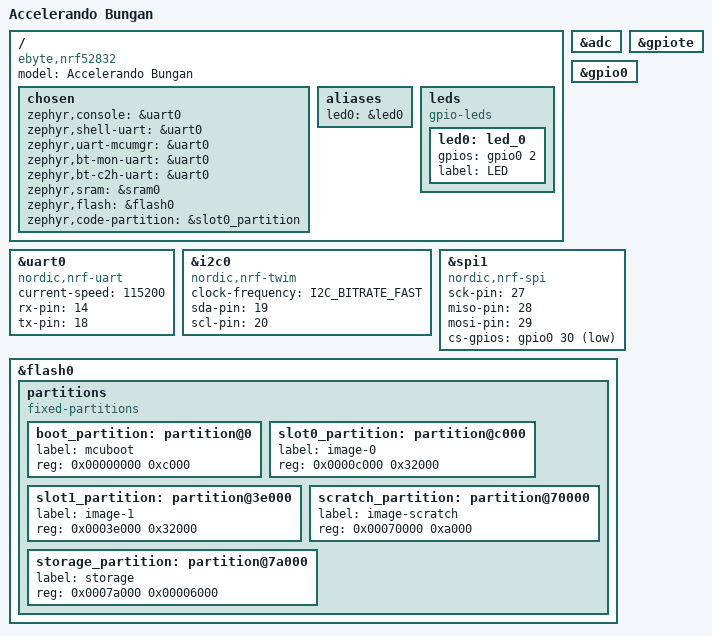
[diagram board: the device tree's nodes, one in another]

/dts-v1/;
#include <nordic/nrf52832_qfaa.dtsi>
#include "accelerando_bungan_d1_bus.dtsi"

/ {
	model = "Accelerando Bungan";

	compatible = "ebyte,nrf52832";

	chosen {
		zephyr,console = &uart0;
		zephyr,shell-uart = &uart0;
		zephyr,uart-mcumgr = &uart0;
		zephyr,bt-mon-uart = &uart0;
		zephyr,bt-c2h-uart = &uart0;
		zephyr,sram = &sram0;
		zephyr,flash = &flash0;
		zephyr,code-partition = &slot0_partition;
	};

	/* These aliases are provided for compatibility with samples */
	aliases {
		led0 = &led0;
	};

	leds {
		compatible = "gpio-leds";
		led0: led_0 {
			gpios = <&gpio0 2 0>;
			label = "LED";
		};
	};
};

&adc {
	status = "okay";
};

&gpiote {
	status = "okay";
};

&gpio0 {
	status = "okay";
};

&uart0 {
	compatible = "nordic,nrf-uart";
	status = "okay";
	current-speed = <115200>;
	status = "okay";
	rx-pin = <14>;
	tx-pin = <18>;
};

&i2c0 {
        compatible = "nordic,nrf-twim";
	status = "okay";
	clock-frequency = <I2C_BITRATE_FAST>;
	sda-pin = <19>;
	scl-pin = <20>;
};

&spi1 {
	compatible = "nordic,nrf-spi";
	status = "okay";
	sck-pin = <27>;
	miso-pin = <28>;
	mosi-pin = <29>;
        cs-gpios = <&gpio0 30 GPIO_ACTIVE_LOW>;
};

&flash0 {
	/*
	 * For more information, see:
	 * http://docs.zephyrproject.org/latest/guides/dts/index.html#flash-partitions
	 */
	partitions {
		compatible = "fixed-partitions";
		#address-cells = <1>;
		#size-cells = <1>;

		boot_partition: partition@0 {
			label = "mcuboot";
			reg = <0x00000000 0xc000>;
		};
		slot0_partition: partition@c000 {
			label = "image-0";
			reg = <0x0000c000 0x32000>;
		};
		slot1_partition: partition@3e000 {
			label = "image-1";
			reg = <0x0003e000 0x32000>;
		};
		scratch_partition: partition@70000 {
			label = "image-scratch";
			reg = <0x00070000 0xa000>;
		};
		storage_partition: partition@7a000 {
			label = "storage";
			reg = <0x0007a000 0x00006000>;
		};
	};
};
